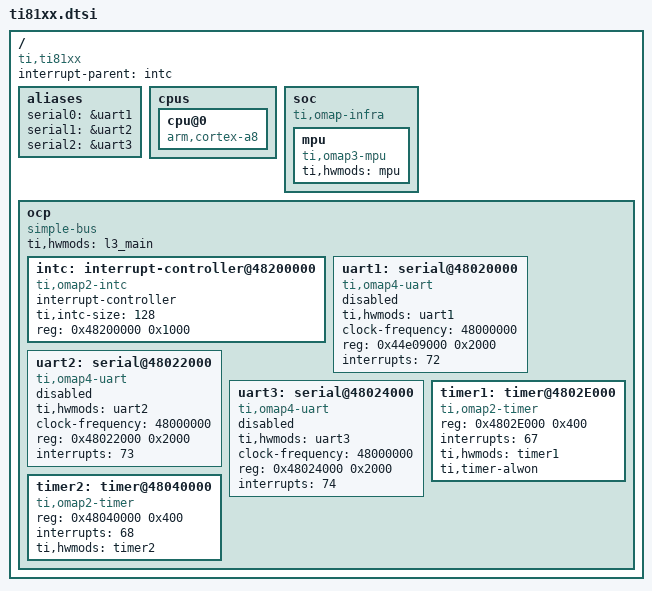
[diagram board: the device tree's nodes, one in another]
/*
 * Device Tree Source for TI81XX SoC
 *
 * Copyright (C) 2012 Texas Instruments Incorporated - http://www.ti.com/
 *
 * This file is licensed under the terms of the GNU General Public License
 * version 2.  This program is licensed "as is" without any warranty of any
 * kind, whether express or implied.
 */

/include/ "skeleton.dtsi"

/ {
	compatible = "ti,ti81xx";
	interrupt-parent = <&intc>;

	aliases {
		serial0 = &uart1;
		serial1 = &uart2;
		serial2 = &uart3;
	};

	cpus {
		cpu@0 {
			compatible = "arm,cortex-a8";
		};
	};

	/*
	 * The soc node represents the soc top level view. It is uses for IPs
	 * that are not memory mapped in the MPU view or for the MPU itself.
	 */
	soc {
		compatible = "ti,omap-infra";
		mpu {
			compatible = "ti,omap3-mpu";
			ti,hwmods = "mpu";
		};
	};

	/*
	 * XXX: Use a flat representation of the TI81XX interconnect.
	 * The real TI81XX interconnect network is quite complex.Since
	 * that will not bring real advantage to represent that in DT
	 * for the moment, just use a fake OCP bus entry to represent
	 * the whole bus hierarchy.
	 */
	ocp {
		compatible = "simple-bus";
		#address-cells = <1>;
		#size-cells = <1>;
		ranges;
		ti,hwmods = "l3_main";

		intc: interrupt-controller@48200000 {
			compatible = "ti,omap2-intc";
			interrupt-controller;
			#interrupt-cells = <1>;
			ti,intc-size = <128>;
			reg = <0x48200000 0x1000>;
		};

		uart1: serial@48020000 {	/* this is UART0 in ch 4 */
			compatible = "ti,omap4-uart";
			ti,hwmods = "uart1";
			clock-frequency = <48000000>;
			reg = <0x44e09000 0x2000>;
			interrupts = <72>;
			status = "disabled";
		};

		uart2: serial@48022000 {
			compatible = "ti,omap4-uart";
			ti,hwmods = "uart2";
			clock-frequency = <48000000>;
			reg = <0x48022000 0x2000>;
			interrupts = <73>;
			status = "disabled";
		};

		uart3: serial@48024000 {
			compatible = "ti,omap4-uart";
			ti,hwmods = "uart3";
			clock-frequency = <48000000>;
			reg = <0x48024000 0x2000>;
			interrupts = <74>;
			status = "disabled";
		};

		timer1: timer@4802E000 {	/* timer1 in ch4 */
			compatible = "ti,omap2-timer";
			reg = <0x4802E000 0x400>;
			interrupts = <67>;
			ti,hwmods = "timer1";
			ti,timer-alwon;
		};

		timer2: timer@48040000 {
			compatible = "ti,omap2-timer";
			reg = <0x48040000 0x400>;
			interrupts = <68>;
			ti,hwmods = "timer2";
		};

	};
};
